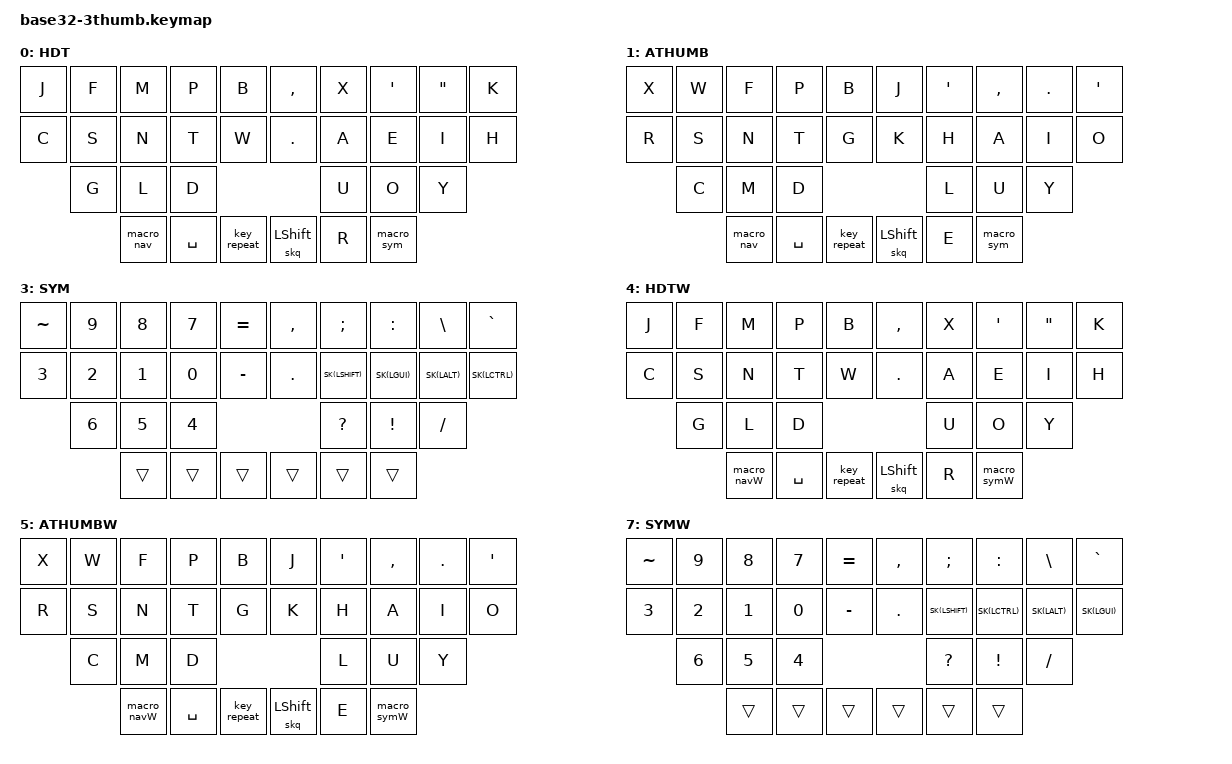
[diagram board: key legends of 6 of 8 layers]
/*
 * Copyright (c) 2020 The ZMK Contributors
 *
 * SPDX-License-Identifier: MIT
 */

#include <behaviors.dtsi>
#include <dt-bindings/zmk/keys.h>
#include <dt-bindings/zmk/bt.h>
#include <dt-bindings/zmk/outputs.h>

#define HDT 0
#define ATHUMB 1
#define NAV 2
#define SYM 3
#define HDTW 4
#define ATHUMBW 5
#define NAVW 6
#define SYMW 7


#define SK(KEY) &nk KEY KEY

#define KEYS_L 0 1 2 3 4 10 11 12 13 14 20 21 22  // left-hand keys
#define KEYS_R 5 6 7 8 9 15 16 17 18 19 23 24 25  // right-hand keys
#define THUMBS 26 27 28 29 30 31                        // thumb keys

&sk {
  release-after-ms = <60000>;
  quick-release;
};

&caps_word {
  continue-list = <UNDERSCORE MINUS BACKSPACE K_CANCEL>;
};

/*                KEY POSITIONS

  ╭────────────────────╮ ╭────────────────────╮
  │  0   1   2   3   4 │ │  5   6   7   8   9 │
  │ 10  11  12  13  14 │ │ 15  16  17  18  19 │
  │     20  21  22     │ │     23  24  25     │
  ╰───────╮ 26  27  28 │ │ 29  30  31 ╭───────╯
          ╰────────────╯ ╰────────────╯            */

/ { 

  behaviors {
    // Sticky key on tap, normal key on hold
    // Useful for modifier-clicking without the modifier remaining active
    nk: not_so_sticky_key {
        compatible = "zmk,behavior-hold-tap";
        label = "NOT_SO_STICKY_KEY";
        #binding-cells = <2>;
        tapping_term_ms = <250>;
        flavor = "tap-preferred";
        bindings = <&kp>, <&sk>;
    };

    skq: sticky_key_quick_release {
      compatible = "zmk,behavior-sticky-key";
      label = "STICKY_KEY_QUICK_RELEASE";
      #binding-cells = <1>;
      bindings = <&kp>;
      quick-release;
      release-after-ms = <750>;
    };

    lal: layer-alpha {
        compatible = "zmk,behavior-hold-tap";
        label = "LAYER_ALPHA";
        #binding-cells = <2>;
        flavor = "balanced";
        tapping-term-ms = <170>;
        quick-tap-ms = <100>;
        global-quick-tap;
        bindings = <&mo>, <&kp>;
    };

        // Swapper for smart alt+tab depends on experimental branch: check west.yml
        swapper: swapper {
            compatible = "zmk,behavior-smart-interrupt";
            label = "SWAPPER";
            #binding-cells = <0>;
            bindings = <&kt LGUI>, <&kp TAB>, <&kt LGUI>;
            shared-key-positions = <1 3 28>;
            timeout-ms = <1000>;
        };

        // Swapper for smart alt+tab depends on experimental branch: check west.yml
        swapperw: swapperw {
            compatible = "zmk,behavior-smart-interrupt";
            label = "SWAPPERW";
            #binding-cells = <0>;
            bindings = <&kt LALT>, <&kp TAB>, <&kt LALT>;
            shared-key-positions = <1 3 28>;
            timeout-ms = <1000>;
        };

        gresc: grave_escape {
            compatible = "zmk,behavior-mod-morph";
            label = "GRAVE_ESCAPE";
            #binding-cells = <0>;
            bindings = <&kp N0>, <&kp DOT>;
            mods = <(MOD_LSFT|MOD_RSFT)>;
            masked_mods = <(MOD_LSFT|MOD_RSFT)>;
        };

        /* left-hand HRMs */
        hrml: hrml {
            compatible = "zmk,behavior-hold-tap";
            label = "hrml";
            #binding-cells = <2>;
            flavor = "balanced";
            tapping-term-ms = <280>;
            quick-tap-ms = <175>;                // double tapping same key allows for repeating
            global-quick-tap-ms = <150>;         // without PR #1387 use global-quick-tap instead
            bindings = <&kp>, <&kp>;
            hold-trigger-key-positions = <KEYS_R THUMBS>;
            hold-trigger-on-release;             // requires PR #1423
        };

        /* right-hand HRMs */
        hrmr: hrmr {
            compatible = "zmk,behavior-hold-tap";
            label = "hrmr";
            #binding-cells = <2>;
            flavor = "balanced";
            tapping-term-ms = <280>;
            quick-tap-ms = <175>;                // double tapping same key allows for repeating
            global-quick-tap-ms = <150>;         // without PR #1387 use global-quick-tap instead
            bindings = <&kp>, <&kp>;
            hold-trigger-key-positions = <KEYS_L THUMBS>;
            hold-trigger-on-release;             // requires PR #1423
        };

    combos {
      #include "combos32-3thumb.dtsi"
    };
    
    macros {
      #include "macros.dtsi"
    };

  };
 
        keymap {
                compatible = "zmk,keymap";
                      
        hdt {
            label = "HDT";
            bindings = <
// ╭─────────────┬─────────────┬─────────────┬─────────────┬─────────────╮   ╭─────────────┬─────────────┬─────────────┬─────────────┬─────────────╮
     &kp J         &kp F         &kp M         &kp P         &kp B             &kp COMMA     &kp X         &kp SQT       &kp DQT       &kp K
     &kp C         &kp S         &kp N         &kp T         &kp W             &kp DOT       &kp A         &kp E         &kp I         &kp H
                   &kp G         &kp L         &kp D                                         &kp U         &kp O         &kp Y
// ╰─────────────┴─────────────┴─────────────┼─────────────┼─────────────┤   ├─────────────┼─────────────┼─────────────┴─────────────┴─────────────╯
                                    &macro_nav    &kp SPACE  &key_repeat       &skq LSHIFT &kp R &macro_sym
//                                           ╰─────────────┴─────────────╯   ╰─────────────┴─────────────╯
            >;
        };

        athumb {
            label = "ATHUMB";
            bindings = <
// ╭─────────────┬─────────────┬─────────────┬─────────────┬─────────────╮   ╭─────────────┬─────────────┬─────────────┬─────────────┬─────────────╮
     &kp X         &kp W         &kp F         &kp P         &kp B             &kp J         &kp SQT       &kp COMMA     &kp DOT       &kp SQT
     &kp R         &kp S         &kp N         &kp T         &kp G             &kp K         &kp H         &kp A         &kp I         &kp O
                   &kp C         &kp M         &kp D                                         &kp L         &kp U         &kp Y 
// ╰─────────────┴─────────────┴─────────────┼─────────────┼─────────────┤   ├─────────────┼─────────────┼─────────────┴─────────────┴─────────────╯
                                     &macro_nav    &kp SPACE  &key_repeat      &skq LSHIFT &kp E  &macro_sym
//                                           ╰─────────────┴─────────────╯   ╰─────────────┴─────────────╯
            >;
        };


        navitation {
            label = "NAV";
            bindings = <
// ╭─────────────┬─────────────┬─────────────┬─────────────┬─────────────╮   ╭─────────────┬─────────────┬─────────────┬─────────────┬─────────────╮
  &kp LC(LA(LS(P)))    &kp ENTER     &kp BACKSPACE  &kp TAB     &kp DELETE      &kp LA(BACKSPACE) &none         &kp UP        &kp LG(Q)  &kp LA(LC(LS(LG(K))))
     SK(LCTRL)         SK(LALT)      SK(LGUI)       SK(LSHIFT)  &kp LG(A)       &kp LG(A)         &kp LEFT      &kp DOWN      &kp RIGHT  &none
                       &kp LG(X)     &kp LG(C)      &kp LG(V)                                     &kp ENTER     &kp BACKSPACE &kp TAB
// ╰─────────────┴─────────────┴─────────────┼─────────────┼─────────────┤   ├─────────────┼─────────────┼─────────────┴─────────────┴─────────────╯
                                               &trans     &trans   &trans     &trans   &trans   &trans
//                                           ╰─────────────┴─────────────╯   ╰─────────────┴─────────────╯
            >;
        };
        symbols {
            label = "SYM";
            bindings = <
// ╭─────────────┬─────────────┬─────────────┬─────────────┬─────────────╮   ╭─────────────┬─────────────┬─────────────┬─────────────┬─────────────╮
     &kp TILDE     &kp N9       &kp N8         &kp N7         &kp EQUAL         &kp COMMA    &kp SEMI      &kp COLON    &kp BSLH      &kp GRAVE
     &kp N3        &kp N2       &kp N1         &kp N0         &kp MINUS         &kp DOT      SK(LSHIFT)    SK(LGUI)     SK(LALT)      SK(LCTRL)
                   &kp N6       &kp N5         &kp N4                                        &kp QMARK     &kp EXCL     &kp SLASH
// ╰─────────────┴─────────────┴─────────────┼─────────────┼─────────────┤   ├─────────────┼─────────────┼─────────────┴─────────────┴─────────────╯
                                               &trans         &trans   &trans &trans         &trans        &trans
//                                           ╰─────────────┴─────────────╯   ╰─────────────┴─────────────╯
            >;
        };

        hdtw {
            label = "HDTW";
            bindings = <
// ╭─────────────┬─────────────┬─────────────┬─────────────┬─────────────╮   ╭─────────────┬─────────────┬─────────────┬─────────────┬─────────────╮
     &kp J         &kp F         &kp M         &kp P         &kp B             &kp COMMA     &kp X         &kp SQT       &kp DQT       &kp K
     &kp C         &kp S         &kp N         &kp T         &kp W             &kp DOT       &kp A         &kp E         &kp I         &kp H
                   &kp G         &kp L         &kp D                                         &kp U         &kp O         &kp Y
// ╰─────────────┴─────────────┴─────────────┼─────────────┼─────────────┤   ├─────────────┼─────────────┼─────────────┴─────────────┴─────────────╯
                                    &macro_navW   &kp SPACE  &key_repeat       &skq LSHIFT  &kp R &macro_symW
//                                           ╰─────────────┴─────────────╯   ╰─────────────┴─────────────╯
            >;
        };

        athumbw {
            label = "ATHUMBW";
            bindings = <
// ╭─────────────┬─────────────┬─────────────┬─────────────┬─────────────╮   ╭─────────────┬─────────────┬─────────────┬─────────────┬─────────────╮
     &kp X         &kp W         &kp F         &kp P         &kp B             &kp J         &kp SQT       &kp COMMA     &kp DOT       &kp SQT
     &kp R         &kp S         &kp N         &kp T         &kp G             &kp K         &kp H         &kp A         &kp I         &kp O
                   &kp C         &kp M         &kp D                                         &kp L         &kp U         &kp Y 
// ╰─────────────┴─────────────┴─────────────┼─────────────┼─────────────┤   ├─────────────┼─────────────┼─────────────┴─────────────┴─────────────╯
                                     &macro_navW    &kp SPACE  &key_repeat     &skq LSHIFT  &kp E  &macro_symW
//                                           ╰─────────────┴─────────────╯   ╰─────────────┴─────────────╯
            >;
        };

        navigation_windows {
            label = "NAVW";
            bindings = <
// ╭─────────────┬─────────────┬─────────────┬─────────────┬─────────────╮   ╭─────────────┬─────────────┬─────────────┬─────────────┬─────────────╮
&kp LC(LA(LS(P)))  &kp ENTER     &kp BACKSPACE  &kp TAB      &kp DELETE        &kp LC(BACKSPACE)  &kp F2        &kp UP        &kp LA(F4)    &none
     SK(LGUI)      SK(LALT)      SK(LCTRL)      SK(LSHIFT)   &kp LC(A)         &kp LC(A)          &kp LEFT      &kp DOWN      &kp RIGHT     &none
                   &kp LC(X)     &kp LC(C)      &kp LC(V)                                         &kp ENTER     &kp BACKSPACE &kp TAB
// ╰─────────────┴─────────────┴─────────────┼─────────────┼─────────────┤   ├─────────────┼─────────────┼─────────────┴─────────────┴─────────────╯
                                               &trans         &trans   &trans &trans         &trans        &trans
//                                           ╰─────────────┴─────────────╯   ╰─────────────┴─────────────╯
            >;
        };

        symbols_windows {
            label = "SYMW";
            bindings = <
// ╭─────────────┬─────────────┬─────────────┬─────────────┬─────────────╮   ╭─────────────┬─────────────┬─────────────┬─────────────┬─────────────╮
     &kp TILDE     &kp N9       &kp N8         &kp N7         &kp EQUAL         &kp COMMA    &kp SEMI      &kp COLON    &kp BSLH      &kp GRAVE
     &kp N3        &kp N2       &kp N1         &kp N0         &kp MINUS         &kp DOT      SK(LSHIFT)    SK(LCTRL)    SK(LALT)      SK(LGUI)
                   &kp N6       &kp N5         &kp N4                                        &kp QMARK     &kp EXCL     &kp SLASH
// ╰─────────────┴─────────────┴─────────────┼─────────────┼─────────────┤   ├─────────────┼─────────────┼─────────────┴─────────────┴─────────────╯
                                               &trans         &trans   &trans &trans         &trans        &trans
//                                           ╰─────────────┴─────────────╯   ╰─────────────┴─────────────╯
            >;
        };
};

};
